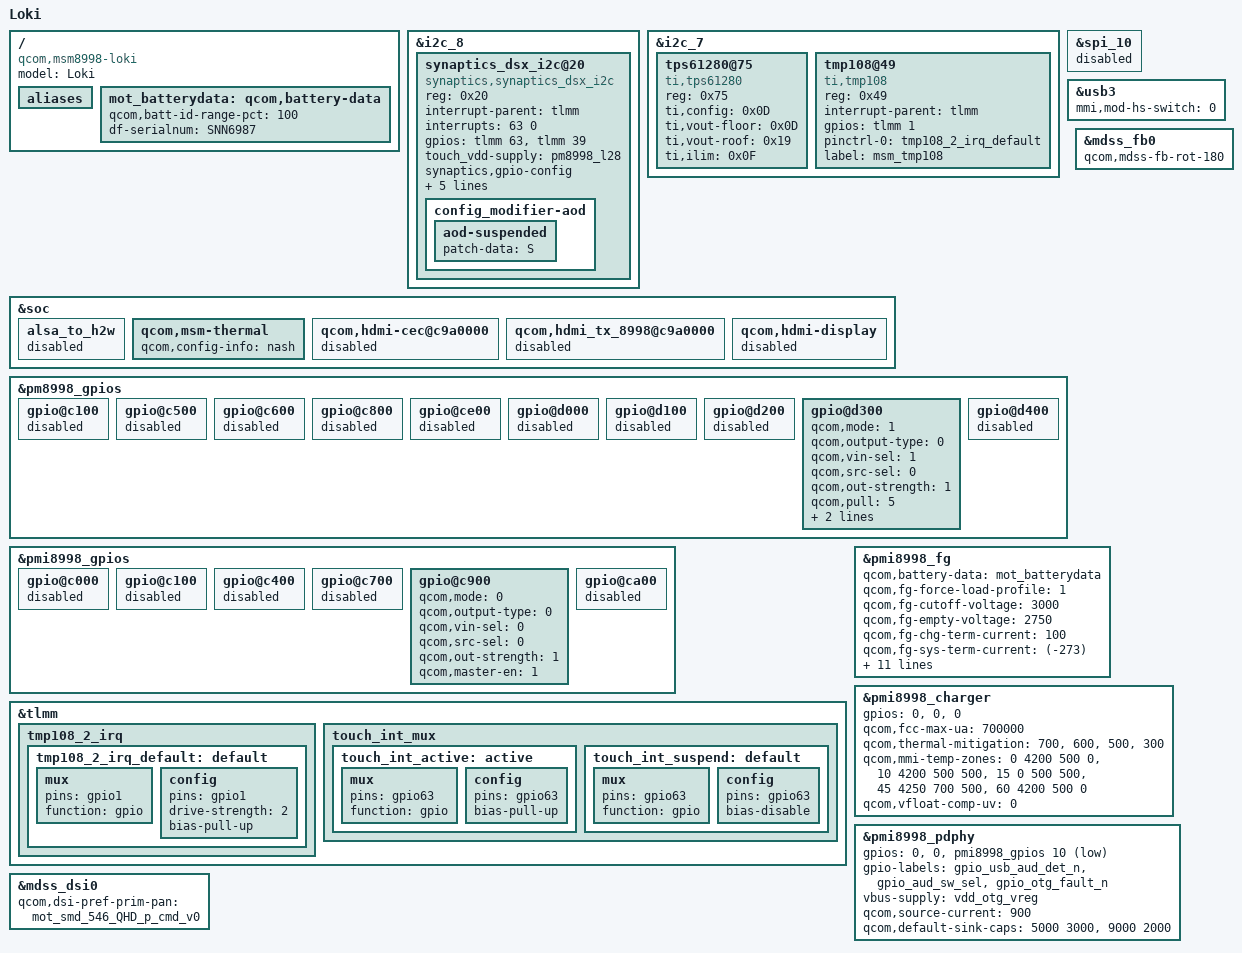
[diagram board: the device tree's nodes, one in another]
/* Copyright (c) 2016, Motorola Mobility Inc. All rights reserved.
 *
 * This program is free software; you can redistribute it and/or modify
 * it under the terms of the GNU General Public License version 2 and
 * only version 2 as published by the Free Software Foundation.
 *
 * This program is distributed in the hope that it will be useful,
 * but WITHOUT ANY WARRANTY; without even the implied warranty of
 * MERCHANTABILITY or FITNESS FOR A PARTICULAR PURPOSE.  See the
 * GNU General Public License for more details.
 */

#include "msm8998-v2.dtsi"
#include "msm8998-moto-common.dtsi"
#include "dsi-panel-mot-smd-546-QHD-g-cmd.dtsi"
#include "dsi-panel-mot-smd-546-QHD-p-cmd.dtsi"

/ {
	model = "Loki";
	compatible = "qcom,msm8998-loki", "qcom,msm8998-moto",
			"qcom,msm8998";

	aliases {
		/delete-property/ spi1;
		/delete-property/ i2c1;
	};
};

&i2c_8 {
	status = "ok";

	synaptics_dsx_i2c@20 {
		compatible = "synaptics,synaptics_dsx_i2c";
		reg = <0x20>;
		interrupt-parent = <&tlmm>;
		interrupts = <63 0>;
		gpios = <&tlmm 63 0>, /* IRQ */
			<&tlmm 39 0>; /* RESET */
		touch_vdd-supply = <&pm8998_l28>;
		synaptics,gpio-config;
		pinctrl-names = "default", "active";
		pinctrl-0 = <&touch_reset_active &touch_int_suspend>;
		pinctrl-1 = <&touch_reset_active &touch_int_active>;
		config_modifier-names = "aod";
		config_modifier-aod {
			aod-suspended {
				/* Power->sleep; */
				patch-data = "S";
			};
		};
	};
};

&i2c_7 {
	tps61280@75 {
		compatible = "ti,tps61280";
		reg = <0x75>;
		ti,config = <0x0D>;
		ti,vout-floor = <0x0D>;
		ti,vout-roof = <0x19>;
		ti,ilim = <0x0F>;
	};

	/delete-node/ analogix_anx78e6@72;

	/delete-node/ drv2624@5a;

	tmp108@49 {
		compatible = "ti,tmp108";
		reg = <0x49>;
		interrupt-parent = <&tlmm>;
		gpios = <&tlmm 1 0>;

		pinctrl-names = "default";
		pinctrl-0 = <&tmp108_2_irq_default>;
		label = "msm_tmp108";
	};

	/delete-node/ cs35l35@41;

	/delete-node/ usb3813@2D;

	/delete-node/ stmvl53l1@29;

	/delete-node/ nq@28;
};

&soc {
	alsa_to_h2w {
	status = "disabled";
	};

	qcom,msm-thermal {
		qcom,config-info = "nash";
	};
	/delete-node/ spi@c175000;

	/delete-node/ qcom,cci@ca0c000;

	/delete-node/ gpio-regulator@22;

	/delete-node/ gpio-regulator@24;

	/delete-node/ gpio-regulator@23;

	/delete-node/ vdd10_anx;

	/delete-node/ mods_codec_shim;

	/delete-node/ sound-9335;
	/delete-node/ sound-tavil;

	/delete-node/ sound;

	/delete-node/ muc;

	/delete-node/ muc_svc@0;

	/delete-node/ dsi_mod_display_driver;

	/delete-node/ apba_ctrl;

	/delete-node/ mod_uart;

	/delete-node/ modbus_switch;

	/delete-node/ mods_v4l2_hal;

	/delete-node/ mods_camera_ext;

	/delete-node/ fpc_fpc1020;

	/delete-node/ msm_cdc_pinctrl@64;

	qcom,hdmi-cec@c9a0000 {
		status = "disabled";
	};

	qcom,hdmi_tx_8998@c9a0000 {
		status = "disabled";
	};

	qcom,hdmi-display {
		status = "disabled";
	};
};

&spi_10 { /* BLSP2 QUP4 */
	status = "disabled";
	/delete-node/ cs47l35@0;
};

&usb3{
	/delete-property/ mmi,mods-support;
	/delete-property/ mod-usb-hub;
	mmi,mod-hs-switch = <0>;
};
&pm8998_gpios {
	gpio@c100 { /* PM8998_GPIO2 */
		status = "disabled";
	};

	gpio@c500 { /* PM8998_GPIO6 */
		status = "disabled";
	};

	gpio@c600 { /* PM8998_GPIO7 */
		status = "disabled";
	};

	gpio@c800 { /* PM8998_GPIO9 */
		status = "disabled";
	};

	gpio@ce00 { /* PM8998_GPIO15 */
		status = "disabled";
	};

	gpio@d000 { /* PM8998_GPIO17*/
		status = "disabled";
	};

	gpio@d100 { /* PM8998_GPIO18 */
		status = "disabled";
	};

	gpio@d200 { /* PM8998_GPIO19 */
		status = "disabled";
	};

	gpio@d300 { /* PM8998_GPIO20 SDX50_S3_RESET_N */
		qcom,mode = <1>;         /* QPNP_PIN_MODE_DIG_OUT */
		qcom,output-type = <0>;  /* QPNP_PIN_OUT_BUF_CMOS */
		qcom,vin-sel = <1>;      /* QPNP_PIN_VIN1 */
		qcom,src-sel = <0>;      /* QPNP_PIN_SEL_FUNC_CONSTANT */
		qcom,out-strength = <1>; /* QPNP_PIN_OUT_STRENGTH_LOW */
		qcom,pull = <5>;	 /* QPNP_PIN_PULL_NO */
		qcom,invert = <1>;	 /* Invert */
		qcom,master-en = <1>;
		status = "ok";
	};

	gpio@d400 { /* PM8998_GPIO21 */
		status = "disabled";
	};
};

&pmi8998_gpios {

	/* ATTENTION!!! PLEASE USE 1.8 V as vin-sel unless high voltage */
	/* is required PMI8998 GPIOs 1, 3, 4, 6, 7, 8, 11 and 13 have */
	/* VIN0 3.6 V and VIN1 1.8 V */

	gpio@c000 { /* PMI8998_GPIO1 */
		status = "disabled";
	};

	gpio@c100 { /* PMI8998_GPIO2 LED2_SRC_RED */
		status = "disabled";
	};

	gpio@c400 { /* PMI8998_GPIO5 LED2_SRC_GREEN */
		status = "disabled";
	};

	gpio@c700 { /* PMI8998_GPIO8 LED2_SRC_BLUE */
		status = "disabled";
	};

	gpio@c900 { /* PMI8998_GPIO10 USB_OTG_FAULT_N */
		qcom,mode = <0>;         /* QPNP_PIN_MODE_DIG_IN */
		qcom,output-type = <0>;  /* QPNP_PIN_OUT_BUF_CMOS */
		qcom,vin-sel = <0>;      /* QPNP_PIN_VIN0 */
		qcom,src-sel = <0>;      /* QPNP_PIN_SEL_FUNC_CONSTANT */
		qcom,out-strength = <1>; /* QPNP_PIN_OUT_STRENGTH_LOW */
		qcom,master-en = <1>;
		status = "okay";
	};

	gpio@ca00 { /* PMI8998_GPIO11 */
		status = "disabled";
	};
};

&tlmm {
	/delete-node/ spi_1;  /* delete spi_1 node in tlmm */

	tmp108_2_irq {
		tmp108_2_irq_default: default {
			mux {
				pins = "gpio1";
				function = "gpio";
			};
			config {
				pins = "gpio1";
				drive-strength = <2>;
				bias-pull-up;
			};
		};
	};

	touch_int_mux {
		touch_int_active: active {
			mux {
				pins = "gpio63";
				function = "gpio";
			};
			config {
				pins = "gpio63";
				bias-pull-up;
			};
		};

		touch_int_suspend: default {
			mux {
				pins = "gpio63";
				function = "gpio";
			};
			config {
				pins = "gpio63";
				bias-disable;
			};
		};
	};
};

&mdss_fb0 {
	qcom,mdss-fb-rot-180;
};

/{
	mot_batterydata: qcom,battery-data {
		qcom,batt-id-range-pct = <100>;
		df-serialnum = "SNN6987";

		#include "batterydata-jw50-lg-pmi8998.dtsi"
	};
};

&pmi8998_fg {
	qcom,battery-data = <&mot_batterydata>;
	qcom,fg-force-load-profile = <1>;
	qcom,fg-cutoff-voltage = <3000>;
	qcom,fg-empty-voltage = <2750>;
	qcom,fg-chg-term-current = <100>;
	qcom,fg-sys-term-current = <(-273)>;
	qcom,fg-delta-soc-thr = <1>;
	qcom,fg-recharge-soc-thr = <1>;
	qcom,fg-rsense-sel = <0>;
	qcom,fg-jeita-thresholds = <(-20)>, <0>, <45>, <60>;
	qcom,cl-start-capacity = <5>;
	qcom,cl-min-temp = <150>;
	qcom,cl-max-temp = <450>;
	qcom,cl-max-increment = <5>;
	qcom,cl-max-decrement = <10>;
	qcom,cl-min-limit = <200>;
	qcom,cl-max-limit = <30>;
};

&pmi8998_charger {
	gpios = <0>,
		<0>,
		<0>;
	qcom,fcc-max-ua = <700000>;

	qcom,thermal-mitigation = <700>,
				   <600>,
				   <500>,
				   <300>;
	qcom,mmi-temp-zones = <0 4200 500 0>,
				<10 4200 500 500>,
				<15 0 500 500>,
				<45 4250 700 500>,
				<60 4200 500 0>;
	qcom,vfloat-comp-uv = <0>;
	/delete-property/ qcom,enable-charging-limit;
	/delete-property/ qcom,upper-limit-capacity;
	/delete-property/ qcom,lower-limit-capacity;
};

&pmi8998_pdphy {
	/delete-property/ pinctrl-names;
	/delete-property/ pinctrl-0;

	gpios = <0>,  /* USB_AUD_DET_N, Not Used*/
		<0>,           /* USB_AUD_SW_SEL, NOT Used*/
		<&pmi8998_gpios 10 1>;  /* USB_OTG_FAULT_N, input */

	gpio-labels = "gpio_usb_aud_det_n",
		"gpio_aud_sw_sel",
		"gpio_otg_fault_n";
	vbus-supply = <&vdd_otg_vreg>;
	qcom,source-current = <900>;
	qcom,default-sink-caps = <5000 3000>, /* 5V @ 3A */
				 <9000 2000>; /* 9V @ 2A */
};

&mdss_dsi0 {
	qcom,dsi-pref-prim-pan = <&mot_smd_546_QHD_p_cmd_v0>;
};
